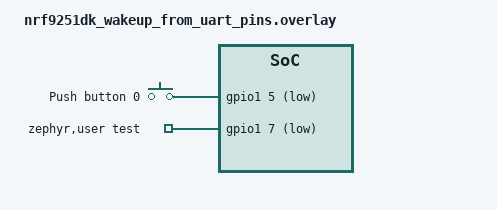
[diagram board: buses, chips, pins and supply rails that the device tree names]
/*
 * Copyright (c) 2026 Nordic Semiconductor ASA
 *
 * SPDX-License-Identifier: LicenseRef-Nordic-5-Clause
 */

/ {
	/*
	 * Redefine sw0/button0 to use RXD0 - P1.05
	 * Thus, when sending character from host, there will be gpio interrupt,
	 * the same as originally triggered by sw0 button.
	 */
	buttons {
		compatible = "gpio-keys";

		button0: button_0 {
			gpios = <&gpio1 5 (GPIO_PULL_UP | GPIO_ACTIVE_LOW)>;
			label = "Push button 0";
			zephyr,code = <INPUT_KEY_0>;
		};
	};

	zephyr,user {
		test-gpios = <&gpio1 7 GPIO_ACTIVE_LOW>;
	};
};

&gpio1 {
	status = "okay";
};

&uart133 {
	status = "disabled";
};
